# YTM32B1LE1 register map
Vendor: YTMicro; File version: 1.0
CPU: CM0PLUS r0p1, little endian, MPU, FPU, 2 interrupt priority bits
Registers are 32-bit, read-write, reset 0x0 unless marked. A register's access mark holds for its fields unless they carry their own. Offsets are from the block's base; [hi:lo] are bit positions.

## DIVSQRT — Divide and Square Root
Base 0x4000E000; register names take the prefix DIVSQRT_
0x00 DEND wo — This register should be loaded with input dividend operand before the divide operation is launched. ewline This register will be updated by hardware during the calculation. ewline Access to this register, while the calculation is not completed, will cause the access to be stalled until the calculation is done.
  [31:0] DIVIDEND rw — This is the input dividend operand for divide calculations.
0x04 DSOR wo — This register should be loaded with input dividend operand before the divide operation is launched. ewline Writing to this register will launch a divide operation if CSR[DFS] is 0. ewline Access to this register, while the calculation is not completed, will cause the access to be stalled until the calculation is done.
  [31:0] DIVISOR rw — This is the input divisor operand for divide calculations.
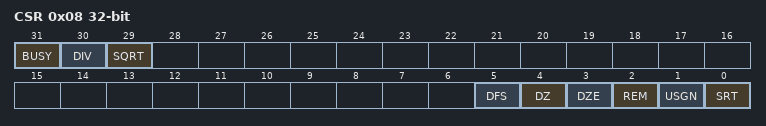
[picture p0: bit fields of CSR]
0x08 CSR — This register includes the configurations and status. ewline Access to this register, while the calculation is not completed, will cause the access to be stalled until the calculation is done.
  [31] BUSY ro — This read-only bit is asserted when DIVSQRT is running a divide or square root calculation. ewline When a calculation is initiated, this bit will be asserted. ewline When a calculation is completed, this bit will be cleared automatically. ewline This bit could be used to poll the DIVSQRT's execution status. ewline The combined [BUSY, DIV, SQRT] indicates the module status ewline - if 3'b001, DIVSQRT is idle and the last calculation is square root ewline - if 3'b010, DIVSQRT is idle and the last calculation is divide ewline - if 3'b101, DIVSQRT is busy processing a square root calculation ewline - if 3'b110, DIVSQRT is busy processing a divide calculation ewline The remaining status of [BUSY, DIV, SQRT] is reserved.
    0=DIVSQRT is idle; 1=DIVSQRT is busy
  [30] DIV ro — This read-only bit indicates the current or last DIVSQRT operation was a divide operation.
    0=Current or last DIVSQRT operation was not a divide operation; 1=Current or last DIVSQRT operation was a divide operation
  [29] SQRT ro — This read-only bit indicates the current or last DIVSQRT operation was a square root
    0=Current or last DIVSQRT operation was not a square root operation; 1=Current or last DIVSQRT operation was a square root operation
  [5] DFS — There are 2 ways for initiating a divide operation. ewline The default way is writing the DSOR register to initiate the divide operation. ewline The other way is writing the CSR[SRT] bit to initiate the divide operation.
    0=A divide operation is initiated by writing DSOR register; 1=A divide operation is initiated by writing CSR[SRT] bit
  [4] DZ ro — This read-only bit indicates the last divide operation had a zero divisor (DSOR == 0). ewline Once this bit is asserted, the read of RES register returns zero or terminates this read with an error if CSR[DZE] is set. ewline This bit will be cleared automatically once the new operation is initiated.
    0=The last divide operation had a non-zero divisor; 1=The last divide operation had a zero divisor
  [3] DZE — This bit controls the response to the divided by zero calculation. ewline If both CSR[DZ] and CSR[DZE] are asserted, the next read of RES register will be terminated with an error.
    0=Read of RES register returns the register content; 1=If CSR[DZ] is set, the next read of RES register will be terminated with an error, else the RES register content are returned
  [2] REM — This bit indicates whether the quotient or the remainder is returned in RES register. ewline The combined [REM, USGN] bits define the following divide operation ewline if 2'b00, perform a signed divide operation and return the quotient ewline if 2'b01, perform a unsigned divide operation and return the quotient ewline if 2'b10, perform a signed divide operation and return the remainder ewline if 2'b11, perform a unsigned divide operation and return the remainder
    0=Return the quotient of divide operation in RES register; 1=Return the remainder of divide operation in RES register
  [1] USGN — This bit indicates whether a signed or unsigned divide operation is performed. ewline Please see the description of CSR[REM] for the definition of divide operation.
    0=Perform a signed divide operation; 1=Perform an unsigned divide operation
  [0] SRT wo — If CSR[DFS] is set, writing 1 to this bit will initiate a divide operation, else is ignored. ewline This bit always reads as a zero.
    0=No operation initialed; 1=IF CSR[DFS] is set, then initiate a divide operation, else will be ignored
0x0C RES — This register is loaded with the result of the divide or square root calculation. ewline It will be updated once the calculation is completed. ewline When a square root operation is performed (on an unsigned 32-bit number), the result is limited to a 16-bit value with RES[31:16] is zero. ewline Any access to the RES register while the module is busy calculating will cause the access to be stalled until the calculation is done and a new result is written into this register.
  [31:0] RESULT — This is the output result for a divide or square root calculation.
0x10 RCND wo — This write-only register is loaded with the square number. ewline Writing this register will initiate a square root calculation. ewline Any access to this register while the module is busy calculating will cause the access to be stalled until the calculation is done. ewline Any read of this read register will cause an error.
  [31:0] RADICAND — This is the input radicand for a square root calculation, that is, the input "square" number.
